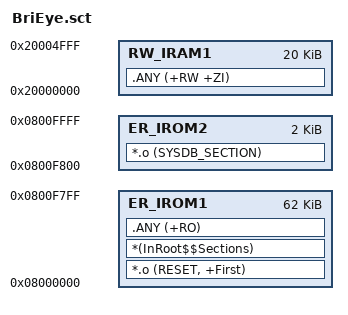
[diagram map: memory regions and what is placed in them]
; *************************************************************
; *** Scatter-Loading Description File generated by uVision ***
; *************************************************************

LR_IROM1 0x08000000 0x00010000  ; load region size_region
{    
	ER_IROM1 0x08000000 0xF800  ; load address = execution address
	{  
		*.o (RESET, +First)
		*(InRoot$$Sections)
		.ANY (+RO)
	}
	ER_IROM2 0x0800F800 0x800
	{
		*.o (SYSDB_SECTION)
	}
	RW_IRAM1 0x20000000 0x5000  ; RW data 
	{  
		.ANY (+RW +ZI)
	}
}

